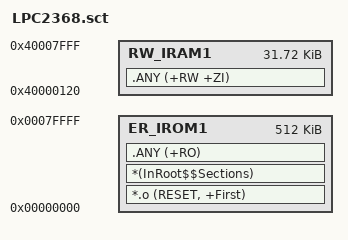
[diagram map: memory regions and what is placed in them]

LR_IROM1 0x00000000 0x80000  {    ; load region size_region
  ER_IROM1 0x00000000 0x80000  {  ; load address = execution address
   *.o (RESET, +First)
   *(InRoot$$Sections)
   .ANY (+RO)
  }
  RW_IRAM1 0x40000120 0x7EE0  {  ; RW data, inc space for realmonitor
   .ANY (+RW +ZI)
  }
}

